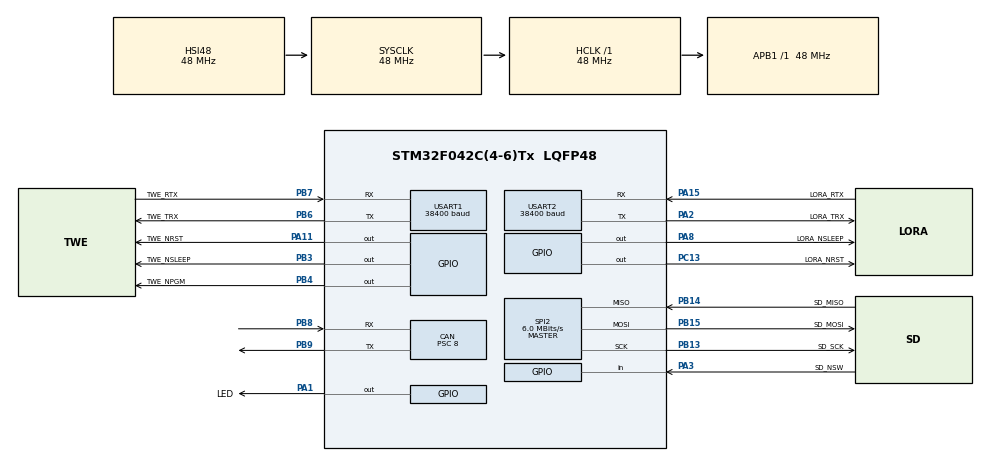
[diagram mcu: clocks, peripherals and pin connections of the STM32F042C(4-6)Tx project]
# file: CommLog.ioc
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CAN.BS1=CAN_BS1_4TQ
CAN.CalculateBaudRate=1000000
CAN.CalculateTimeBit=1000
CAN.CalculateTimeQuantum=166.66666666666666
CAN.Prescaler=8
Dma.Request0=USART1_RX
Dma.Request1=USART1_TX
Dma.Request2=USART2_RX
Dma.Request3=USART2_TX
Dma.USART1_RX.0.Direction=DMA_PERIPH_TO_MEMORY
Dma.USART1_RX.0.Instance=DMA1_Channel3
Dma.USART1_RX.0.MemDataAlignment=DMA_MDATAALIGN_BYTE
Dma.USART1_RX.0.MemInc=DMA_MINC_ENABLE
Dma.USART1_RX.0.Mode=DMA_CIRCULAR
Dma.USART1_RX.0.PeriphDataAlignment=DMA_PDATAALIGN_BYTE
Dma.USART1_RX.0.PeriphInc=DMA_PINC_DISABLE
Dma.USART1_RX.0.Priority=DMA_PRIORITY_MEDIUM
Dma.USART1_TX.1.Direction=DMA_MEMORY_TO_PERIPH
Dma.USART1_TX.1.Instance=DMA1_Channel2
Dma.USART1_TX.1.MemDataAlignment=DMA_MDATAALIGN_BYTE
Dma.USART1_TX.1.MemInc=DMA_MINC_ENABLE
Dma.USART1_TX.1.Mode=DMA_NORMAL
Dma.USART1_TX.1.PeriphDataAlignment=DMA_PDATAALIGN_BYTE
Dma.USART1_TX.1.PeriphInc=DMA_PINC_DISABLE
Dma.USART1_TX.1.Priority=DMA_PRIORITY_LOW
Dma.USART2_RX.2.Direction=DMA_PERIPH_TO_MEMORY
Dma.USART2_RX.2.Instance=DMA1_Channel5
Dma.USART2_RX.2.MemDataAlignment=DMA_MDATAALIGN_BYTE
Dma.USART2_RX.2.MemInc=DMA_MINC_ENABLE
Dma.USART2_RX.2.Mode=DMA_CIRCULAR
Dma.USART2_RX.2.PeriphDataAlignment=DMA_PDATAALIGN_BYTE
Dma.USART2_RX.2.PeriphInc=DMA_PINC_DISABLE
Dma.USART2_RX.2.Priority=DMA_PRIORITY_LOW
Dma.USART2_TX.3.Direction=DMA_MEMORY_TO_PERIPH
Dma.USART2_TX.3.Instance=DMA1_Channel4
Dma.USART2_TX.3.MemDataAlignment=DMA_MDATAALIGN_BYTE
Dma.USART2_TX.3.MemInc=DMA_MINC_ENABLE
Dma.USART2_TX.3.Mode=DMA_NORMAL
Dma.USART2_TX.3.PeriphDataAlignment=DMA_PDATAALIGN_BYTE
Dma.USART2_TX.3.PeriphInc=DMA_PINC_DISABLE
Dma.USART2_TX.3.Priority=DMA_PRIORITY_LOW
FATFS._CODE_PAGE=1
FATFS._FS_LOCK=1
FATFS._FS_TIMEOUT=100
FATFS._MAX_LFN=32
FATFS._MAX_SS=512
FATFS._USE_LFN=0
IWDG.Prescaler=IWDG_PRESCALER_64
IWDG.Reload=4095
IWDG.Window=4095
Mcu.Family=STM32F0
Mcu.Name=STM32F042C(4-6)Tx
Mcu.Package=LQFP48
NVIC.CEC_CAN_IRQn=true\:3\:0\:true\:false\:true\:true\:true\:true
NVIC.DMA1_Channel2_3_IRQn=true\:2\:0\:true\:false\:true\:false\:true\:true
NVIC.DMA1_Channel4_5_IRQn=true\:2\:0\:true\:false\:true\:false\:true\:true
NVIC.SPI2_IRQn=true\:1\:0\:true\:false\:true\:true\:true\:true
PA1.GPIO_Label=LED
PA1.Signal=GPIO_Output
PA11.GPIO_Label=TWE_NRST
PA11.GPIO_ModeDefaultOutputPP=GPIO_MODE_OUTPUT_OD
PA11.GPIO_PuPd=GPIO_PULLUP
PA11.PinState=GPIO_PIN_SET
PA11.Signal=GPIO_Output
PA13.Mode=Serial_Wire
PA13.Signal=SYS_SWDIO
PA14.Mode=Serial_Wire
PA14.Signal=SYS_SWCLK
PA15.GPIO_Label=LORA_RTX
PA15.GPIO_ModeDefaultPP=GPIO_MODE_AF_OD
PA15.GPIO_PuPd=GPIO_PULLUP
PA15.Mode=Asynchronous
PA15.Signal=USART2_RX
PA2.GPIO_Label=LORA_TRX
PA2.GPIO_ModeDefaultPP=GPIO_MODE_AF_OD
PA2.GPIO_PuPd=GPIO_PULLUP
PA2.Mode=Asynchronous
PA2.Signal=USART2_TX
PA3.GPIO_Label=SD_NSW
PA3.GPIO_PuPd=GPIO_PULLUP
PA3.Signal=GPIO_Input
PA8.GPIO_Label=LORA_NSLEEP
PA8.GPIO_ModeDefaultOutputPP=GPIO_MODE_OUTPUT_OD
PA8.GPIO_PuPd=GPIO_PULLUP
PA8.PinState=GPIO_PIN_SET
PA8.Signal=GPIO_Output
PB13.GPIO_Label=SD_SCK
PB13.Mode=Full_Duplex_Master
PB13.Signal=SPI2_SCK
PB14.GPIO_Label=SD_MISO
PB14.GPIO_PuPd=GPIO_PULLUP
PB14.Mode=Full_Duplex_Master
PB14.Signal=SPI2_MISO
PB15.GPIO_Label=SD_MOSI
PB15.GPIO_PuPd=GPIO_PULLUP
PB15.Mode=Full_Duplex_Master
PB15.Signal=SPI2_MOSI
PB3.GPIO_Label=TWE_NSLEEP
PB3.GPIO_ModeDefaultOutputPP=GPIO_MODE_OUTPUT_OD
PB3.GPIO_PuPd=GPIO_PULLUP
PB3.PinState=GPIO_PIN_SET
PB3.Signal=GPIO_Output
PB4.GPIO_Label=TWE_NPGM
PB4.GPIO_ModeDefaultOutputPP=GPIO_MODE_OUTPUT_OD
PB4.GPIO_PuPd=GPIO_PULLUP
PB4.PinState=GPIO_PIN_SET
PB4.Signal=GPIO_Output
PB6.GPIO_Label=TWE_TRX
PB6.GPIO_ModeDefaultPP=GPIO_MODE_AF_OD
PB6.GPIO_PuPd=GPIO_PULLUP
PB6.Mode=Asynchronous
PB6.Signal=USART1_TX
PB7.GPIO_Label=TWE_RTX
PB7.GPIO_ModeDefaultPP=GPIO_MODE_AF_OD
PB7.GPIO_PuPd=GPIO_PULLUP
PB7.Mode=Asynchronous
PB7.Signal=USART1_RX
PB8.GPIO_PuPd=GPIO_PULLUP
PB8.Mode=CAN_Activate
PB8.Signal=CAN_RX
PB9.Mode=CAN_Activate
PB9.Signal=CAN_TX
PC13.GPIO_Label=LORA_NRST
PC13.GPIO_ModeDefaultOutputPP=GPIO_MODE_OUTPUT_OD
PC13.GPIO_PuPd=GPIO_PULLUP
PC13.PinState=GPIO_PIN_SET
PC13.Signal=GPIO_Output
ProjectManager.HeapSize=0x200
ProjectManager.StackSize=0x400
ProjectManager.TargetToolchain=STM32CubeIDE
RCC.AHBFreq_Value=48000000
RCC.APB1Freq_Value=48000000
RCC.APB1TimFreq_Value=48000000
RCC.HCLKFreq_Value=48000000
RCC.SYSCLKFreq_VALUE=48000000
RCC.SYSCLKSource=RCC_SYSCLKSOURCE_HSI48
SPI2.BaudRatePrescaler=SPI_BAUDRATEPRESCALER_8
SPI2.CalculateBaudRate=6.0 MBits/s
SPI2.DataSize=SPI_DATASIZE_8BIT
SPI2.Direction=SPI_DIRECTION_2LINES
SPI2.Mode=SPI_MODE_MASTER
SPI2.NSSPMode=SPI_NSS_PULSE_DISABLE
SPI2.VirtualType=VM_MASTER
USART1.BaudRate=38400
USART1.OverrunDisableParam=ADVFEATURE_OVERRUN_ENABLE
USART1.VirtualMode-Asynchronous=VM_ASYNC
USART2.BaudRate=38400
USART2.VirtualMode-Asynchronous=VM_ASYNC
VP_FATFS_VS_Generic.Mode=User_defined
VP_IWDG_VS_IWDG.Mode=IWDG_Activate
board=custom

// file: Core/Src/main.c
/* USER CODE BEGIN Header */
/**
  ******************************************************************************
  * @file           : main.c
  * @brief          : Main program body
  ******************************************************************************
  * @attention
  *
  * Copyright (c) 2023 STMicroelectronics.
  * All rights reserved.
  *
  * This software is licensed under terms that can be found in the LICENSE file
  * in the root directory of this software component.
  * If no LICENSE file comes with this software, it is provided AS-IS.
  *
  ******************************************************************************
  */
/* USER CODE END Header */
#include "main.h"
#include "fatfs.h"

/* USER CODE BEGIN Includes */
#include "app.h"
/* USER CODE END Includes */

CAN_HandleTypeDef hcan;

IWDG_HandleTypeDef hiwdg;

SPI_HandleTypeDef hspi2;

UART_HandleTypeDef huart1;
UART_HandleTypeDef huart2;
DMA_HandleTypeDef hdma_usart1_rx;
DMA_HandleTypeDef hdma_usart1_tx;
DMA_HandleTypeDef hdma_usart2_rx;
DMA_HandleTypeDef hdma_usart2_tx;

void SystemClock_Config(void);
static void MX_GPIO_Init(void);
static void MX_DMA_Init(void);
static void MX_USART1_UART_Init(void);
static void MX_CAN_Init(void);
static void MX_IWDG_Init(void);
static void MX_SPI2_Init(void);
static void MX_USART2_UART_Init(void);
/* USER CODE BEGIN PFP */
void initialise_monitor_handles(void);
/* USER CODE END PFP */

int main(void)
{
  /* USER CODE BEGIN 1 */

#ifdef DEBUG
  initialise_monitor_handles();
#endif

  /* USER CODE END 1 */

  /* MCU Configuration--------------------------------------------------------*/

  /* Reset of all peripherals, Initializes the Flash interface and the Systick. */
  HAL_Init();

  /* Configure the system clock */
  SystemClock_Config();

  /* Initialize all configured peripherals */
  MX_GPIO_Init();
  MX_DMA_Init();
  MX_USART1_UART_Init();
  MX_CAN_Init();
  MX_IWDG_Init();
  MX_SPI2_Init();
  MX_FATFS_Init();
  MX_USART2_UART_Init();
  /* USER CODE BEGIN 2 */
  setup();
  /* USER CODE END 2 */

  /* Infinite loop */
  while (1)
  {

    /* USER CODE BEGIN 3 */
    loop();

#ifndef DEBUG
//    HAL_IWDG_Refresh(&hiwdg);
#endif
  }
  /* USER CODE END 3 */
}

void SystemClock_Config(void)
{
  RCC_OscInitTypeDef RCC_OscInitStruct = {0};
  RCC_ClkInitTypeDef RCC_ClkInitStruct = {0};
  RCC_PeriphCLKInitTypeDef PeriphClkInit = {0};

  /** Initializes the RCC Oscillators according to the specified parameters
  * in the RCC_OscInitTypeDef structure.
  */
  RCC_OscInitStruct.OscillatorType = RCC_OSCILLATORTYPE_HSI48|RCC_OSCILLATORTYPE_LSI;
  RCC_OscInitStruct.HSI48State = RCC_HSI48_ON;
  RCC_OscInitStruct.LSIState = RCC_LSI_ON;
  RCC_OscInitStruct.PLL.PLLState = RCC_PLL_NONE;
  if (HAL_RCC_OscConfig(&RCC_OscInitStruct) != HAL_OK)
  {
    Error_Handler();
  }

  /** Initializes the CPU, AHB and APB buses clocks
  */
  RCC_ClkInitStruct.ClockType = RCC_CLOCKTYPE_HCLK|RCC_CLOCKTYPE_SYSCLK
                              |RCC_CLOCKTYPE_PCLK1;
  RCC_ClkInitStruct.SYSCLKSource = RCC_SYSCLKSOURCE_HSI48;
  RCC_ClkInitStruct.AHBCLKDivider = RCC_SYSCLK_DIV1;
  RCC_ClkInitStruct.APB1CLKDivider = RCC_HCLK_DIV1;

  if (HAL_RCC_ClockConfig(&RCC_ClkInitStruct, FLASH_LATENCY_1) != HAL_OK)
  {
    Error_Handler();
  }
  PeriphClkInit.PeriphClockSelection = RCC_PERIPHCLK_USART1;
  PeriphClkInit.Usart1ClockSelection = RCC_USART1CLKSOURCE_PCLK1;
  if (HAL_RCCEx_PeriphCLKConfig(&PeriphClkInit) != HAL_OK)
  {
    Error_Handler();
  }
}

static void MX_CAN_Init(void)
{

  hcan.Instance = CAN;
  hcan.Init.Prescaler = 8;
  hcan.Init.Mode = CAN_MODE_NORMAL;
  hcan.Init.SyncJumpWidth = CAN_SJW_1TQ;
  hcan.Init.TimeSeg1 = CAN_BS1_4TQ;
  hcan.Init.TimeSeg2 = CAN_BS2_1TQ;
  hcan.Init.TimeTriggeredMode = DISABLE;
  hcan.Init.AutoBusOff = DISABLE;
  hcan.Init.AutoWakeUp = DISABLE;
  hcan.Init.AutoRetransmission = DISABLE;
  hcan.Init.ReceiveFifoLocked = DISABLE;
  hcan.Init.TransmitFifoPriority = DISABLE;
  if (HAL_CAN_Init(&hcan) != HAL_OK)
  {
    Error_Handler();
  }

}

static void MX_IWDG_Init(void)
{

  /* USER CODE BEGIN IWDG_Init 0 */
  return;
#ifdef DEBUG
  return;
#endif

  /* USER CODE END IWDG_Init 0 */

  hiwdg.Instance = IWDG;
  hiwdg.Init.Prescaler = IWDG_PRESCALER_64;
  hiwdg.Init.Window = 4095;
  hiwdg.Init.Reload = 4095;
  if (HAL_IWDG_Init(&hiwdg) != HAL_OK)
  {
    Error_Handler();
  }

}

static void MX_SPI2_Init(void)
{

  /* SPI2 parameter configuration*/
  hspi2.Instance = SPI2;
  hspi2.Init.Mode = SPI_MODE_MASTER;
  hspi2.Init.Direction = SPI_DIRECTION_2LINES;
  hspi2.Init.DataSize = SPI_DATASIZE_8BIT;
  hspi2.Init.CLKPolarity = SPI_POLARITY_LOW;
  hspi2.Init.CLKPhase = SPI_PHASE_1EDGE;
  hspi2.Init.NSS = SPI_NSS_SOFT;
  hspi2.Init.BaudRatePrescaler = SPI_BAUDRATEPRESCALER_8;
  hspi2.Init.FirstBit = SPI_FIRSTBIT_MSB;
  hspi2.Init.TIMode = SPI_TIMODE_DISABLE;
  hspi2.Init.CRCCalculation = SPI_CRCCALCULATION_DISABLE;
  hspi2.Init.CRCPolynomial = 7;
  hspi2.Init.CRCLength = SPI_CRC_LENGTH_DATASIZE;
  hspi2.Init.NSSPMode = SPI_NSS_PULSE_DISABLE;
  if (HAL_SPI_Init(&hspi2) != HAL_OK)
  {
    Error_Handler();
  }

}

static void MX_USART1_UART_Init(void)
{

  huart1.Instance = USART1;
  huart1.Init.BaudRate = 38400;
  huart1.Init.WordLength = UART_WORDLENGTH_8B;
  huart1.Init.StopBits = UART_STOPBITS_1;
  huart1.Init.Parity = UART_PARITY_NONE;
  huart1.Init.Mode = UART_MODE_TX_RX;
  huart1.Init.HwFlowCtl = UART_HWCONTROL_NONE;
  huart1.Init.OverSampling = UART_OVERSAMPLING_16;
  huart1.Init.OneBitSampling = UART_ONE_BIT_SAMPLE_DISABLE;
  huart1.AdvancedInit.AdvFeatureInit = UART_ADVFEATURE_NO_INIT;
  if (HAL_UART_Init(&huart1) != HAL_OK)
  {
    Error_Handler();
  }

}

static void MX_USART2_UART_Init(void)
{

  huart2.Instance = USART2;
  huart2.Init.BaudRate = 38400;
  huart2.Init.WordLength = UART_WORDLENGTH_8B;
  huart2.Init.StopBits = UART_STOPBITS_1;
  huart2.Init.Parity = UART_PARITY_NONE;
  huart2.Init.Mode = UART_MODE_TX_RX;
  huart2.Init.HwFlowCtl = UART_HWCONTROL_NONE;
  huart2.Init.OverSampling = UART_OVERSAMPLING_16;
  huart2.Init.OneBitSampling = UART_ONE_BIT_SAMPLE_DISABLE;
  huart2.AdvancedInit.AdvFeatureInit = UART_ADVFEATURE_NO_INIT;
  if (HAL_UART_Init(&huart2) != HAL_OK)
  {
    Error_Handler();
  }

}

static void MX_DMA_Init(void)
{

  /* DMA controller clock enable */
  __HAL_RCC_DMA1_CLK_ENABLE();

  /* DMA interrupt init */
  /* DMA1_Channel2_3_IRQn interrupt configuration */
  HAL_NVIC_SetPriority(DMA1_Channel2_3_IRQn, 2, 0);
  HAL_NVIC_EnableIRQ(DMA1_Channel2_3_IRQn);
  /* DMA1_Channel4_5_IRQn interrupt configuration */
  HAL_NVIC_SetPriority(DMA1_Channel4_5_IRQn, 2, 0);
  HAL_NVIC_EnableIRQ(DMA1_Channel4_5_IRQn);

}

static void MX_GPIO_Init(void)
{
  GPIO_InitTypeDef GPIO_InitStruct = {0};

  /* GPIO Ports Clock Enable */
  __HAL_RCC_GPIOC_CLK_ENABLE();
  __HAL_RCC_GPIOA_CLK_ENABLE();
  __HAL_RCC_GPIOB_CLK_ENABLE();

  /*Configure GPIO pin Output Level */
  HAL_GPIO_WritePin(LORA_NRST_GPIO_Port, LORA_NRST_Pin, GPIO_PIN_SET);

  /*Configure GPIO pin Output Level */
  HAL_GPIO_WritePin(LED_GPIO_Port, LED_Pin, GPIO_PIN_RESET);

  /*Configure GPIO pin Output Level */
  HAL_GPIO_WritePin(GPIOA, LORA_NSLEEP_Pin|TWE_NRST_Pin, GPIO_PIN_SET);

  /*Configure GPIO pin Output Level */
  HAL_GPIO_WritePin(GPIOB, TWE_NSLEEP_Pin|TWE_NPGM_Pin, GPIO_PIN_SET);

  /*Configure GPIO pin : LORA_NRST_Pin */
  GPIO_InitStruct.Pin = LORA_NRST_Pin;
  GPIO_InitStruct.Mode = GPIO_MODE_OUTPUT_OD;
  GPIO_InitStruct.Pull = GPIO_PULLUP;
  GPIO_InitStruct.Speed = GPIO_SPEED_FREQ_LOW;
  HAL_GPIO_Init(LORA_NRST_GPIO_Port, &GPIO_InitStruct);

  /*Configure GPIO pin : LED_Pin */
  GPIO_InitStruct.Pin = LED_Pin;
  GPIO_InitStruct.Mode = GPIO_MODE_OUTPUT_PP;
  GPIO_InitStruct.Pull = GPIO_NOPULL;
  GPIO_InitStruct.Speed = GPIO_SPEED_FREQ_LOW;
  HAL_GPIO_Init(LED_GPIO_Port, &GPIO_InitStruct);

  /*Configure GPIO pin : SD_NSW_Pin */
  GPIO_InitStruct.Pin = SD_NSW_Pin;
  GPIO_InitStruct.Mode = GPIO_MODE_INPUT;
  GPIO_InitStruct.Pull = GPIO_PULLUP;
  HAL_GPIO_Init(SD_NSW_GPIO_Port, &GPIO_InitStruct);

  /*Configure GPIO pins : LORA_NSLEEP_Pin TWE_NRST_Pin */
  GPIO_InitStruct.Pin = LORA_NSLEEP_Pin|TWE_NRST_Pin;
  GPIO_InitStruct.Mode = GPIO_MODE_OUTPUT_OD;
  GPIO_InitStruct.Pull = GPIO_PULLUP;
  GPIO_InitStruct.Speed = GPIO_SPEED_FREQ_LOW;
  HAL_GPIO_Init(GPIOA, &GPIO_InitStruct);

  /*Configure GPIO pins : TWE_NSLEEP_Pin TWE_NPGM_Pin */
  GPIO_InitStruct.Pin = TWE_NSLEEP_Pin|TWE_NPGM_Pin;
  GPIO_InitStruct.Mode = GPIO_MODE_OUTPUT_OD;
  GPIO_InitStruct.Pull = GPIO_PULLUP;
  GPIO_InitStruct.Speed = GPIO_SPEED_FREQ_LOW;
  HAL_GPIO_Init(GPIOB, &GPIO_InitStruct);

}

void Error_Handler(void)
{
  __disable_irq();
  while (1)
  {
  }
}
